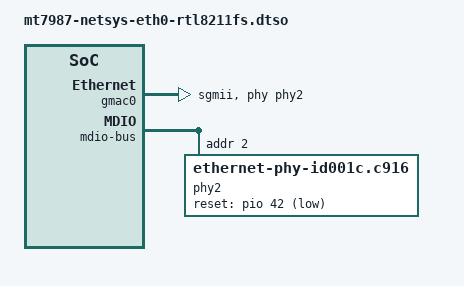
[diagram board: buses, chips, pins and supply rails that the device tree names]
// SPDX-License-Identifier: (GPL-2.0 OR MIT)

/dts-v1/;
/plugin/;

/ {
	fragment@0 {
		target = <&gmac0>;
		__overlay__ {
			mac-type = "gdm";
			phy-mode = "sgmii";
			phy-handle = <&phy2>;
			managed = "in-band-status";
			status = "okay";
		};
	};

	fragment@1 {
		target-path = "/soc_netsys/ethernet@15100000/mdio-bus";
		__overlay__ {
			phy2: phy@2 {
				compatible = "ethernet-phy-id001c.c916";
				reg = <2>;
				reset-gpios = <&pio 42 1>;
				reset-assert-us = <10000>;
				reset-deassert-us = <50000>;
				phy-mode = "sgmii";
				realtek,clkout-disable;
				realtek,aldps-enable;
			};
		};
	};

	fragment@2 {
		target-path = "/soc_netsys/hnat@15000000";
		__overlay__ {
			mtketh-lan = "eth0";
		};
	};
};

